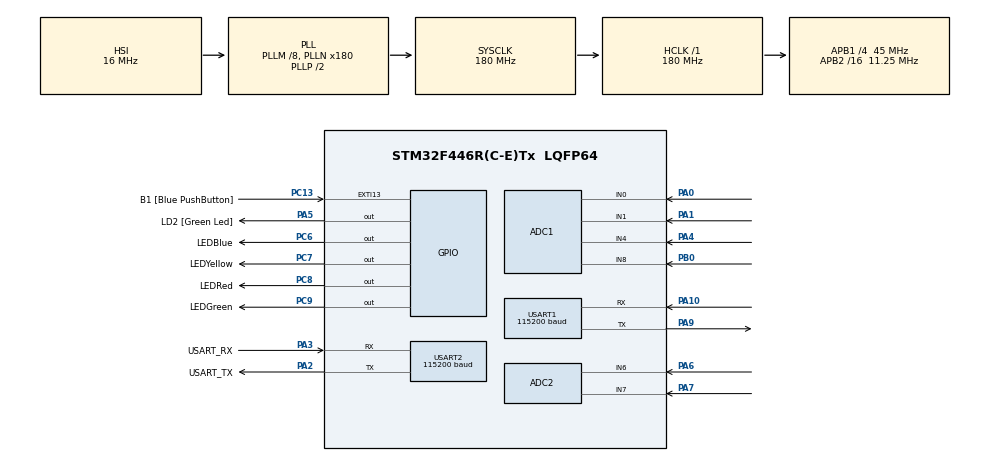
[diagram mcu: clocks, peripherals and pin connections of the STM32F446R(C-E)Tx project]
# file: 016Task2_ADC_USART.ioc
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ADC1.Channel-0\#ChannelRegularConversion=ADC_CHANNEL_0
ADC1.Channel-1\#ChannelRegularConversion=ADC_CHANNEL_1
ADC1.Channel-2\#ChannelRegularConversion=ADC_CHANNEL_4
ADC1.Channel-3\#ChannelRegularConversion=ADC_CHANNEL_6
ADC1.Channel-4\#ChannelRegularConversion=ADC_CHANNEL_7
ADC1.Channel-5\#ChannelRegularConversion=ADC_CHANNEL_8
ADC1.ClockPrescaler=ADC_CLOCK_SYNC_PCLK_DIV8
ADC1.ContinuousConvMode=ENABLE
ADC1.DMAContinuousRequests=ENABLE
ADC1.EOCSelection=ADC_EOC_SEQ_CONV
ADC1.NbrOfConversion=6
ADC1.NbrOfConversionFlag=1
ADC1.Rank-0\#ChannelRegularConversion=1
ADC1.Rank-1\#ChannelRegularConversion=2
ADC1.Rank-2\#ChannelRegularConversion=3
ADC1.Rank-3\#ChannelRegularConversion=4
ADC1.Rank-4\#ChannelRegularConversion=5
ADC1.Rank-5\#ChannelRegularConversion=6
ADC1.SamplingTime-0\#ChannelRegularConversion=ADC_SAMPLETIME_480CYCLES
ADC1.SamplingTime-1\#ChannelRegularConversion=ADC_SAMPLETIME_480CYCLES
ADC1.SamplingTime-2\#ChannelRegularConversion=ADC_SAMPLETIME_480CYCLES
ADC1.SamplingTime-3\#ChannelRegularConversion=ADC_SAMPLETIME_480CYCLES
ADC1.SamplingTime-4\#ChannelRegularConversion=ADC_SAMPLETIME_480CYCLES
ADC1.SamplingTime-5\#ChannelRegularConversion=ADC_SAMPLETIME_480CYCLES
ADC1.ScanConvMode=ENABLE
ADC1.master=1
ADC2.Channel-0\#ChannelRegularConversion=ADC_CHANNEL_4
ADC2.Channel-2\#ChannelRegularConversion=ADC_CHANNEL_6
ADC2.Channel-3\#ChannelRegularConversion=ADC_CHANNEL_7
ADC2.ClockPrescaler=ADC_CLOCK_SYNC_PCLK_DIV8
ADC2.ContinuousConvMode=ENABLE
ADC2.DMAContinuousRequests=ENABLE
ADC2.EOCSelection=ADC_EOC_SEQ_CONV
ADC2.InjNumberOfConversion=0
ADC2.NbrOfConversion=3
ADC2.NbrOfConversionFlag=1
ADC2.Rank-0\#ChannelRegularConversion=1
ADC2.Rank-2\#ChannelRegularConversion=2
ADC2.Rank-3\#ChannelRegularConversion=3
ADC2.SamplingTime-0\#ChannelRegularConversion=ADC_SAMPLETIME_480CYCLES
ADC2.SamplingTime-2\#ChannelRegularConversion=ADC_SAMPLETIME_480CYCLES
ADC2.SamplingTime-3\#ChannelRegularConversion=ADC_SAMPLETIME_480CYCLES
Dma.ADC1.0.Direction=DMA_PERIPH_TO_MEMORY
Dma.ADC1.0.FIFOMode=DMA_FIFOMODE_DISABLE
Dma.ADC1.0.Instance=DMA2_Stream0
Dma.ADC1.0.MemDataAlignment=DMA_MDATAALIGN_HALFWORD
Dma.ADC1.0.MemInc=DMA_MINC_ENABLE
Dma.ADC1.0.Mode=DMA_CIRCULAR
Dma.ADC1.0.PeriphDataAlignment=DMA_PDATAALIGN_HALFWORD
Dma.ADC1.0.PeriphInc=DMA_PINC_DISABLE
Dma.ADC1.0.Priority=DMA_PRIORITY_LOW
Dma.ADC2.1.Direction=DMA_PERIPH_TO_MEMORY
Dma.ADC2.1.FIFOMode=DMA_FIFOMODE_DISABLE
Dma.ADC2.1.Instance=DMA2_Stream2
Dma.ADC2.1.MemDataAlignment=DMA_MDATAALIGN_HALFWORD
Dma.ADC2.1.MemInc=DMA_MINC_ENABLE
Dma.ADC2.1.Mode=DMA_CIRCULAR
Dma.ADC2.1.PeriphDataAlignment=DMA_PDATAALIGN_HALFWORD
Dma.ADC2.1.PeriphInc=DMA_PINC_DISABLE
Dma.ADC2.1.Priority=DMA_PRIORITY_LOW
Dma.Request0=ADC1
Dma.Request1=ADC2
Mcu.Family=STM32F4
Mcu.Name=STM32F446R(C-E)Tx
Mcu.Package=LQFP64
NVIC.ADC_IRQn=true\:6\:0\:true\:false\:true\:true\:true\:true
NVIC.DMA2_Stream0_IRQn=true\:6\:0\:true\:false\:true\:false\:true\:true
NVIC.DMA2_Stream2_IRQn=true\:6\:0\:true\:false\:true\:false\:true\:true
NVIC.EXTI15_10_IRQn=true\:6\:0\:true\:false\:true\:true\:true\:true
NVIC.PriorityGroup=NVIC_PRIORITYGROUP_4
NVIC.TIM6_DAC_IRQn=true\:15\:0\:false\:false\:true\:false\:true\:true
NVIC.TimeBase=TIM6_DAC_IRQn
NVIC.TimeBaseIP=TIM6
NVIC.USART1_IRQn=true\:0\:0\:false\:false\:true\:true\:true\:true
PA0-WKUP.Signal=ADCx_IN0
PA1.Signal=ADCx_IN1
PA10.Mode=Asynchronous
PA10.Signal=USART1_RX
PA13.GPIO_Label=TMS
PA13.Mode=Serial_Wire
PA13.Signal=SYS_JTMS-SWDIO
PA14.GPIO_Label=TCK
PA14.Mode=Serial_Wire
PA14.Signal=SYS_JTCK-SWCLK
PA2.GPIO_Label=USART_TX
PA2.Mode=Asynchronous
PA2.Signal=USART2_TX
PA3.GPIO_Label=USART_RX
PA3.Mode=Asynchronous
PA3.Signal=USART2_RX
PA4.Signal=ADCx_IN4
PA5.GPIO_Label=LD2 [Green Led]
PA5.Signal=GPIO_Output
PA6.Signal=ADCx_IN6
PA7.Signal=ADCx_IN7
PA9.Mode=Asynchronous
PA9.Signal=USART1_TX
PB0.Signal=ADCx_IN8
PB3.GPIO_Label=SWO
PB3.Signal=SYS_JTDO-SWO
PC13.GPIO_Label=B1 [Blue PushButton]
PC13.GPIO_ModeDefaultEXTI=GPIO_MODE_IT_FALLING
PC13.Signal=GPXTI13
PC14-OSC32_IN.Mode=LSE-External-Oscillator
PC14-OSC32_IN.Signal=RCC_OSC32_IN
PC15-OSC32_OUT.Mode=LSE-External-Oscillator
PC15-OSC32_OUT.Signal=RCC_OSC32_OUT
PC6.GPIO_Label=LEDBlue
PC6.GPIO_ModeDefaultOutputPP=GPIO_MODE_OUTPUT_OD
PC6.GPIO_PuPd=GPIO_NOPULL
PC6.GPIO_Speed=GPIO_SPEED_FREQ_HIGH
PC6.Signal=GPIO_Output
PC7.GPIO_Label=LEDYellow
PC7.GPIO_ModeDefaultOutputPP=GPIO_MODE_OUTPUT_OD
PC7.GPIO_PuPd=GPIO_NOPULL
PC7.GPIO_Speed=GPIO_SPEED_FREQ_HIGH
PC7.Signal=GPIO_Output
PC8.GPIO_Label=LEDRed
PC8.GPIO_ModeDefaultOutputPP=GPIO_MODE_OUTPUT_OD
PC8.GPIO_PuPd=GPIO_NOPULL
PC8.GPIO_Speed=GPIO_SPEED_FREQ_HIGH
PC8.Signal=GPIO_Output
PC9.GPIO_Label=LEDGreen
PC9.GPIO_ModeDefaultOutputPP=GPIO_MODE_OUTPUT_OD
PC9.GPIO_PuPd=GPIO_NOPULL
PC9.GPIO_Speed=GPIO_SPEED_FREQ_HIGH
PC9.Signal=GPIO_Output
PH0-OSC_IN.Mode=HSE-External-Oscillator
PH0-OSC_IN.Signal=RCC_OSC_IN
PH1-OSC_OUT.Mode=HSE-External-Oscillator
PH1-OSC_OUT.Signal=RCC_OSC_OUT
ProjectManager.HeapSize=0x200
ProjectManager.StackSize=0x400
ProjectManager.TargetToolchain=STM32CubeIDE
RCC.48MHZClocksFreq_Value=84000000
RCC.AHBFreq_Value=180000000
RCC.APB1CLKDivider=RCC_HCLK_DIV4
RCC.APB1Freq_Value=45000000
RCC.APB1TimFreq_Value=90000000
RCC.APB2CLKDivider=RCC_HCLK_DIV16
RCC.APB2Freq_Value=11250000
RCC.APB2TimFreq_Value=22500000
RCC.CortexFreq_Value=180000000
RCC.FLatency-AdvancedSettings=FLASH_LATENCY_5
RCC.HCLKFreq_Value=180000000
RCC.HSE_VALUE=8000000
RCC.HSI_VALUE=16000000
RCC.PLLM=8
RCC.PLLN=180
RCC.SYSCLKFreq_VALUE=180000000
RCC.SYSCLKSource=RCC_SYSCLKSOURCE_PLLCLK
RCC.USBFreq_Value=180000000
RCC.VCOOutputFreq_Value=360000000
SH.ADCx_IN0.0=ADC1_IN0,IN0
SH.ADCx_IN1.0=ADC1_IN1,IN1
SH.ADCx_IN4.0=ADC1_IN4,IN4
SH.ADCx_IN4.1=ADC2_IN4,IN4
SH.ADCx_IN6.0=ADC2_IN6,IN6
SH.ADCx_IN6.1=ADC1_IN6,IN6
SH.ADCx_IN7.0=ADC2_IN7,IN7
SH.ADCx_IN7.1=ADC1_IN7,IN7
SH.ADCx_IN8.0=ADC1_IN8,IN8
USART1.BaudRate=115200
USART1.VirtualMode=VM_ASYNC
USART2.BaudRate=115200
USART2.VirtualMode=VM_ASYNC
VP_SYS_VS_tim6.Mode=TIM6
board=NUCLEO-F446RE

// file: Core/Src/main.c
/* USER CODE BEGIN Header */
/**
 ******************************************************************************
 * @file           : main.c
 * @brief          : Main program body
 ******************************************************************************
 * @attention
 *
 * Copyright (c) 2025 STMicroelectronics.
 * All rights reserved.
 *
 * This software is licensed under terms that can be found in the LICENSE file
 * in the root directory of this software component.
 * If no LICENSE file comes with this software, it is provided AS-IS.
 *
 ******************************************************************************
 */
/* USER CODE END Header */
#include "main.h"
#include "adc.h"
#include "dma.h"
#include "usart.h"
#include "gpio.h"

/* USER CODE BEGIN Includes */
#include "../../AppFiles/Inc/process.h"
/* USER CODE END Includes */

/* USER CODE BEGIN PTD */

#if configUSE_TIMERS == 1
UART_HandleTypeDef huart2;
#endif
// 	USE ANYONE AT A TIME
//	SEGGER		:	1
// 	Tera Term 	:	0

/* USER CODE END PTD */

void SystemClock_Config(void);

int main(void)
{

  /* MCU Configuration--------------------------------------------------------*/

  /* Reset of all peripherals, Initializes the Flash interface and the Systick. */
  HAL_Init();

  /* Configure the system clock */
  SystemClock_Config();

  /* Initialize all configured peripherals */
  MX_GPIO_Init();
  MX_DMA_Init();
  MX_USART2_UART_Init();
  MX_ADC1_Init();
  MX_ADC2_Init();
  MX_USART1_UART_Init();
  /* USER CODE BEGIN 2 */

#if DEBUG_WITH_SEGGER == 1
	SEGGER_UART_init(SEGGER_BAUD_RATE);
#endif

	//***********************************************************************
	//							RTOS Init
	//***********************************************************************
	RTOSOneTimeInit();

#if DEBUG_WITH_SEGGER == 1
    SEGGER_SYSVIEW_Conf();
#endif
	//***********************************************************************
	//							 Process One Time Init
	//***********************************************************************
	ProcessOneTimeInit();

	//***********************************************************************
	//							RTOS : Task Scheduler Starts
	//***********************************************************************
	{
		//<-----------------------Task Scheduler Starts---------------------->
		vTaskStartScheduler();
	}

  /* USER CODE END 2 */

  /* Infinite loop */
	while (1) {

	}
}

void SystemClock_Config(void)
{
  RCC_OscInitTypeDef RCC_OscInitStruct = {0};
  RCC_ClkInitTypeDef RCC_ClkInitStruct = {0};

  /** Configure the main internal regulator output voltage
  */
  __HAL_RCC_PWR_CLK_ENABLE();
  __HAL_PWR_VOLTAGESCALING_CONFIG(PWR_REGULATOR_VOLTAGE_SCALE1);

  /** Initializes the RCC Oscillators according to the specified parameters
  * in the RCC_OscInitTypeDef structure.
  */
  RCC_OscInitStruct.OscillatorType = RCC_OSCILLATORTYPE_HSI;
  RCC_OscInitStruct.HSIState = RCC_HSI_ON;
  RCC_OscInitStruct.HSICalibrationValue = RCC_HSICALIBRATION_DEFAULT;
  RCC_OscInitStruct.PLL.PLLState = RCC_PLL_ON;
  RCC_OscInitStruct.PLL.PLLSource = RCC_PLLSOURCE_HSI;
  RCC_OscInitStruct.PLL.PLLM = 8;
  RCC_OscInitStruct.PLL.PLLN = 180;
  RCC_OscInitStruct.PLL.PLLP = RCC_PLLP_DIV2;
  RCC_OscInitStruct.PLL.PLLQ = 2;
  RCC_OscInitStruct.PLL.PLLR = 2;
  if (HAL_RCC_OscConfig(&RCC_OscInitStruct) != HAL_OK)
  {
    Error_Handler();
  }

  /** Activate the Over-Drive mode
  */
  if (HAL_PWREx_EnableOverDrive() != HAL_OK)
  {
    Error_Handler();
  }

  /** Initializes the CPU, AHB and APB buses clocks
  */
  RCC_ClkInitStruct.ClockType = RCC_CLOCKTYPE_HCLK|RCC_CLOCKTYPE_SYSCLK
                              |RCC_CLOCKTYPE_PCLK1|RCC_CLOCKTYPE_PCLK2;
  RCC_ClkInitStruct.SYSCLKSource = RCC_SYSCLKSOURCE_PLLCLK;
  RCC_ClkInitStruct.AHBCLKDivider = RCC_SYSCLK_DIV1;
  RCC_ClkInitStruct.APB1CLKDivider = RCC_HCLK_DIV4;
  RCC_ClkInitStruct.APB2CLKDivider = RCC_HCLK_DIV16;

  if (HAL_RCC_ClockConfig(&RCC_ClkInitStruct, FLASH_LATENCY_5) != HAL_OK)
  {
    Error_Handler();
  }
}

void HAL_TIM_PeriodElapsedCallback(TIM_HandleTypeDef *htim)
{
  if (htim->Instance == TIM6)
  {
    HAL_IncTick();
  }
}

void Error_Handler(void)
{
	__disable_irq();
	while (1) {
	}
}
